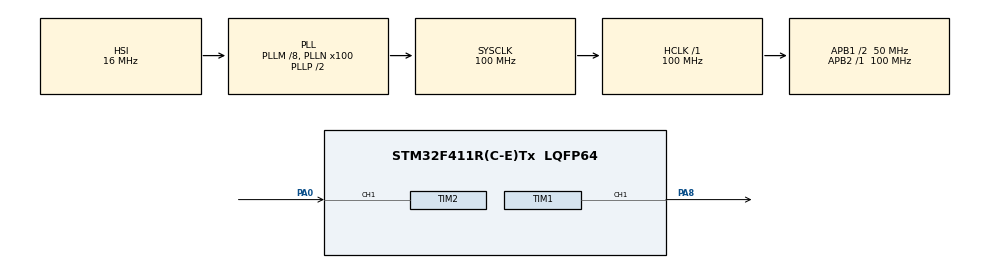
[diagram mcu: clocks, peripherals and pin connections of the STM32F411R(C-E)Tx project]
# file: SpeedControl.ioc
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Dma.Request0=TIM2_CH1
Dma.TIM2_CH1.0.Direction=DMA_PERIPH_TO_MEMORY
Dma.TIM2_CH1.0.FIFOMode=DMA_FIFOMODE_DISABLE
Dma.TIM2_CH1.0.Instance=DMA1_Stream5
Dma.TIM2_CH1.0.MemDataAlignment=DMA_MDATAALIGN_WORD
Dma.TIM2_CH1.0.MemInc=DMA_MINC_ENABLE
Dma.TIM2_CH1.0.Mode=DMA_CIRCULAR
Dma.TIM2_CH1.0.PeriphDataAlignment=DMA_PDATAALIGN_WORD
Dma.TIM2_CH1.0.PeriphInc=DMA_PINC_DISABLE
Dma.TIM2_CH1.0.Priority=DMA_PRIORITY_LOW
Mcu.Family=STM32F4
Mcu.Name=STM32F411R(C-E)Tx
Mcu.Package=LQFP64
NVIC.DMA1_Stream5_IRQn=true\:0\:0\:false\:false\:true\:false\:true\:true
NVIC.PriorityGroup=NVIC_PRIORITYGROUP_4
PA0-WKUP.Signal=S_TIM2_CH1_ETR
PA8.Signal=S_TIM1_CH1
ProjectManager.HeapSize=0x200
ProjectManager.StackSize=0x400
ProjectManager.TargetToolchain=STM32CubeIDE
RCC.48MHZClocksFreq_Value=50000000
RCC.AHBFreq_Value=100000000
RCC.APB1CLKDivider=RCC_HCLK_DIV2
RCC.APB1Freq_Value=50000000
RCC.APB1TimFreq_Value=100000000
RCC.APB2Freq_Value=100000000
RCC.APB2TimFreq_Value=100000000
RCC.CortexFreq_Value=100000000
RCC.HCLKFreq_Value=100000000
RCC.HSE_VALUE=25000000
RCC.HSI_VALUE=16000000
RCC.LSE_VALUE=32768
RCC.PLLM=8
RCC.PLLN=100
RCC.SYSCLKFreq_VALUE=100000000
RCC.SYSCLKSource=RCC_SYSCLKSOURCE_PLLCLK
RCC.VCOOutputFreq_Value=200000000
SH.S_TIM1_CH1.0=TIM1_CH1,PWM Generation1 CH1
SH.S_TIM2_CH1_ETR.0=TIM2_CH1,Input_Capture1_from_TI1
TIM1.Channel-PWM\ Generation1\ CH1=TIM_CHANNEL_1
TIM1.Period=99
TIM1.Prescaler=99
TIM1.Pulse-PWM\ Generation1\ CH1=50
TIM2.Channel-Input_Capture1_from_TI1=TIM_CHANNEL_1
TIM2.Period=4294967295
TIM2.Prescaler=99
VP_TIM1_VS_ClockSourceINT.Mode=Internal
VP_TIM2_VS_ClockSourceINT.Mode=Internal
board=custom

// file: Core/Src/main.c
/* USER CODE BEGIN Header */
/**
  ******************************************************************************
  * @file           : main.c
  * @brief          : Main program body
  ******************************************************************************
  * @attention
  *
  * Copyright (c) 2023 STMicroelectronics.
  * All rights reserved.
  *
  * This software is licensed under terms that can be found in the LICENSE file
  * in the root directory of this software component.
  * If no LICENSE file comes with this software, it is provided AS-IS.
  *
  ******************************************************************************
  */
/* USER CODE END Header */
#include "main.h"

/* USER CODE BEGIN Includes */
#define IC_BUFFER_SIZE 20
/* USER CODE END Includes */

TIM_HandleTypeDef htim1;
TIM_HandleTypeDef htim2;
DMA_HandleTypeDef hdma_tim2_ch1;

/* USER CODE BEGIN PV */
uint32_t InputCaptureBuffer[IC_BUFFER_SIZE];
float dt;
float error;
float Speed;
uint32_t sumdiff;
uint8_t MotorSetRPM;
uint8_t L_MotorSetRPM;
uint8_t duty = 50;
GPIO_PinState set;
/* USER CODE END PV */

void SystemClock_Config(void);
static void MX_GPIO_Init(void);
static void MX_DMA_Init(void);
static void MX_TIM2_Init(void);
static void MX_TIM1_Init(void);
/* USER CODE BEGIN PFP */
float ReadEncoder();
void Controller();
/* USER CODE END PFP */

int main(void)
{

  /* MCU Configuration--------------------------------------------------------*/

  /* Reset of all peripherals, Initializes the Flash interface and the Systick. */
    HAL_Init();

  /* Configure the system clock */
  SystemClock_Config();

  /* Initialize all configured peripherals */
  MX_GPIO_Init();
  MX_DMA_Init();
  MX_TIM2_Init();
  MX_TIM1_Init();
  /* USER CODE BEGIN 2 */
HAL_TIM_Base_Start(&htim2);
HAL_TIM_IC_Start_DMA(&htim2, TIM_CHANNEL_1, InputCaptureBuffer, IC_BUFFER_SIZE);

HAL_TIM_Base_Start(&htim1);
HAL_TIM_PWM_Start(&htim1, TIM_CHANNEL_1);
  /* USER CODE END 2 */

  /* Infinite loop */
  /* USER CODE BEGIN WHILE */
  while (1)
  	  {
	  static uint32_t timestamp = 0;
	  if (HAL_GetTick() >= timestamp){
		  timestamp = HAL_GetTick() + 50;
		  dt = ReadEncoder();
		  if (dt > 0){
			  Speed = (60.0*1000000.0)/(12.0*dt*64.0);
		  }
		  if (set == 0){
			  __HAL_TIM_SET_COMPARE(&htim1, TIM_CHANNEL_1, duty);
		  }
		  else if (set == 1){
			  Controller();
		  }
	  }
    /* USER CODE END WHILE */

  }
}

void SystemClock_Config(void)
{
  RCC_OscInitTypeDef RCC_OscInitStruct = {0};
  RCC_ClkInitTypeDef RCC_ClkInitStruct = {0};

  /** Configure the main internal regulator output voltage
  */
  __HAL_RCC_PWR_CLK_ENABLE();
  __HAL_PWR_VOLTAGESCALING_CONFIG(PWR_REGULATOR_VOLTAGE_SCALE1);

  /** Initializes the RCC Oscillators according to the specified parameters
  * in the RCC_OscInitTypeDef structure.
  */
  RCC_OscInitStruct.OscillatorType = RCC_OSCILLATORTYPE_HSI;
  RCC_OscInitStruct.HSIState = RCC_HSI_ON;
  RCC_OscInitStruct.HSICalibrationValue = RCC_HSICALIBRATION_DEFAULT;
  RCC_OscInitStruct.PLL.PLLState = RCC_PLL_ON;
  RCC_OscInitStruct.PLL.PLLSource = RCC_PLLSOURCE_HSI;
  RCC_OscInitStruct.PLL.PLLM = 8;
  RCC_OscInitStruct.PLL.PLLN = 100;
  RCC_OscInitStruct.PLL.PLLP = RCC_PLLP_DIV2;
  RCC_OscInitStruct.PLL.PLLQ = 4;
  if (HAL_RCC_OscConfig(&RCC_OscInitStruct) != HAL_OK)
  {
    Error_Handler();
  }

  /** Initializes the CPU, AHB and APB buses clocks
  */
  RCC_ClkInitStruct.ClockType = RCC_CLOCKTYPE_HCLK|RCC_CLOCKTYPE_SYSCLK
                              |RCC_CLOCKTYPE_PCLK1|RCC_CLOCKTYPE_PCLK2;
  RCC_ClkInitStruct.SYSCLKSource = RCC_SYSCLKSOURCE_PLLCLK;
  RCC_ClkInitStruct.AHBCLKDivider = RCC_SYSCLK_DIV1;
  RCC_ClkInitStruct.APB1CLKDivider = RCC_HCLK_DIV2;
  RCC_ClkInitStruct.APB2CLKDivider = RCC_HCLK_DIV1;

  if (HAL_RCC_ClockConfig(&RCC_ClkInitStruct, FLASH_LATENCY_3) != HAL_OK)
  {
    Error_Handler();
  }
}

static void MX_TIM1_Init(void)
{

  TIM_ClockConfigTypeDef sClockSourceConfig = {0};
  TIM_MasterConfigTypeDef sMasterConfig = {0};
  TIM_OC_InitTypeDef sConfigOC = {0};
  TIM_BreakDeadTimeConfigTypeDef sBreakDeadTimeConfig = {0};

  htim1.Instance = TIM1;
  htim1.Init.Prescaler = 99;
  htim1.Init.CounterMode = TIM_COUNTERMODE_UP;
  htim1.Init.Period = 99;
  htim1.Init.ClockDivision = TIM_CLOCKDIVISION_DIV1;
  htim1.Init.RepetitionCounter = 0;
  htim1.Init.AutoReloadPreload = TIM_AUTORELOAD_PRELOAD_DISABLE;
  if (HAL_TIM_Base_Init(&htim1) != HAL_OK)
  {
    Error_Handler();
  }
  sClockSourceConfig.ClockSource = TIM_CLOCKSOURCE_INTERNAL;
  if (HAL_TIM_ConfigClockSource(&htim1, &sClockSourceConfig) != HAL_OK)
  {
    Error_Handler();
  }
  if (HAL_TIM_PWM_Init(&htim1) != HAL_OK)
  {
    Error_Handler();
  }
  sMasterConfig.MasterOutputTrigger = TIM_TRGO_RESET;
  sMasterConfig.MasterSlaveMode = TIM_MASTERSLAVEMODE_DISABLE;
  if (HAL_TIMEx_MasterConfigSynchronization(&htim1, &sMasterConfig) != HAL_OK)
  {
    Error_Handler();
  }
  sConfigOC.OCMode = TIM_OCMODE_PWM1;
  sConfigOC.Pulse = 50;
  sConfigOC.OCPolarity = TIM_OCPOLARITY_HIGH;
  sConfigOC.OCNPolarity = TIM_OCNPOLARITY_HIGH;
  sConfigOC.OCFastMode = TIM_OCFAST_DISABLE;
  sConfigOC.OCIdleState = TIM_OCIDLESTATE_RESET;
  sConfigOC.OCNIdleState = TIM_OCNIDLESTATE_RESET;
  if (HAL_TIM_PWM_ConfigChannel(&htim1, &sConfigOC, TIM_CHANNEL_1) != HAL_OK)
  {
    Error_Handler();
  }
  sBreakDeadTimeConfig.OffStateRunMode = TIM_OSSR_DISABLE;
  sBreakDeadTimeConfig.OffStateIDLEMode = TIM_OSSI_DISABLE;
  sBreakDeadTimeConfig.LockLevel = TIM_LOCKLEVEL_OFF;
  sBreakDeadTimeConfig.DeadTime = 0;
  sBreakDeadTimeConfig.BreakState = TIM_BREAK_DISABLE;
  sBreakDeadTimeConfig.BreakPolarity = TIM_BREAKPOLARITY_HIGH;
  sBreakDeadTimeConfig.AutomaticOutput = TIM_AUTOMATICOUTPUT_DISABLE;
  if (HAL_TIMEx_ConfigBreakDeadTime(&htim1, &sBreakDeadTimeConfig) != HAL_OK)
  {
    Error_Handler();
  }
  HAL_TIM_MspPostInit(&htim1);

}

static void MX_TIM2_Init(void)
{

  TIM_ClockConfigTypeDef sClockSourceConfig = {0};
  TIM_MasterConfigTypeDef sMasterConfig = {0};
  TIM_IC_InitTypeDef sConfigIC = {0};

  htim2.Instance = TIM2;
  htim2.Init.Prescaler = 99;
  htim2.Init.CounterMode = TIM_COUNTERMODE_UP;
  htim2.Init.Period = 4294967295;
  htim2.Init.ClockDivision = TIM_CLOCKDIVISION_DIV1;
  htim2.Init.AutoReloadPreload = TIM_AUTORELOAD_PRELOAD_DISABLE;
  if (HAL_TIM_Base_Init(&htim2) != HAL_OK)
  {
    Error_Handler();
  }
  sClockSourceConfig.ClockSource = TIM_CLOCKSOURCE_INTERNAL;
  if (HAL_TIM_ConfigClockSource(&htim2, &sClockSourceConfig) != HAL_OK)
  {
    Error_Handler();
  }
  if (HAL_TIM_IC_Init(&htim2) != HAL_OK)
  {
    Error_Handler();
  }
  sMasterConfig.MasterOutputTrigger = TIM_TRGO_RESET;
  sMasterConfig.MasterSlaveMode = TIM_MASTERSLAVEMODE_DISABLE;
  if (HAL_TIMEx_MasterConfigSynchronization(&htim2, &sMasterConfig) != HAL_OK)
  {
    Error_Handler();
  }
  sConfigIC.ICPolarity = TIM_INPUTCHANNELPOLARITY_RISING;
  sConfigIC.ICSelection = TIM_ICSELECTION_DIRECTTI;
  sConfigIC.ICPrescaler = TIM_ICPSC_DIV1;
  sConfigIC.ICFilter = 0;
  if (HAL_TIM_IC_ConfigChannel(&htim2, &sConfigIC, TIM_CHANNEL_1) != HAL_OK)
  {
    Error_Handler();
  }

}

static void MX_DMA_Init(void)
{

  /* DMA controller clock enable */
  __HAL_RCC_DMA1_CLK_ENABLE();

  /* DMA interrupt init */
  /* DMA1_Stream5_IRQn interrupt configuration */
  HAL_NVIC_SetPriority(DMA1_Stream5_IRQn, 0, 0);
  HAL_NVIC_EnableIRQ(DMA1_Stream5_IRQn);

}

static void MX_GPIO_Init(void)
{

  /* GPIO Ports Clock Enable */
  __HAL_RCC_GPIOA_CLK_ENABLE();

}

/* USER CODE BEGIN 4 */
float ReadEncoder()
{
	uint32_t currentDMAPointer = IC_BUFFER_SIZE - __HAL_DMA_GET_COUNTER(htim2.hdma[1]);

	uint32_t lastValidDMAPointer = (currentDMAPointer-1 + IC_BUFFER_SIZE) % IC_BUFFER_SIZE;

	uint32_t i = (lastValidDMAPointer + IC_BUFFER_SIZE - 10) % IC_BUFFER_SIZE;

	sumdiff = 0;

	while (i != lastValidDMAPointer)
	{
		uint32_t firstCapture = InputCaptureBuffer[i];

		uint32_t NextCapture = InputCaptureBuffer[(i+1)%IC_BUFFER_SIZE];
		sumdiff += NextCapture - firstCapture;
		i = (i+1) % IC_BUFFER_SIZE;

	}
	return  (sumdiff/10.0);
}

void Controller(){
	if (L_MotorSetRPM != MotorSetRPM)
	{
		duty = 0.0927*(MotorSetRPM * MotorSetRPM) + 1.2244*(MotorSetRPM) + 6.806;
		__HAL_TIM_SET_COMPARE(&htim1, TIM_CHANNEL_1, duty);
	}
	else if (L_MotorSetRPM == MotorSetRPM)
	{
		if (MotorSetRPM == 0){
			duty = 0;
		}
		else{
			error = MotorSetRPM - Speed;
			if (error > 0){
				duty += 1;
			}
			else if (error < 0){
				duty -= 1;
			}
		}
		if (duty >= 99){
			duty = 99;
		}
		else if (duty <= 1)
		{
			duty = 1;
		}
		__HAL_TIM_SET_COMPARE(&htim1, TIM_CHANNEL_1, duty);
	}
	L_MotorSetRPM = MotorSetRPM;
}
/* USER CODE END 4 */

void Error_Handler(void)
{
  __disable_irq();
  while (1)
  {
  }
}
